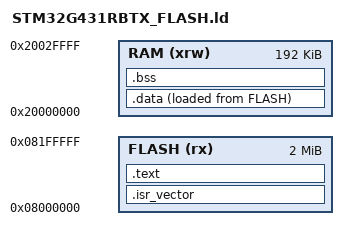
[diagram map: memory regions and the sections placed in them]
ENTRY(Reset_Handler)

_estack = 0x20030000;

MEMORY
{
    FLASH (rx) : ORIGIN = 0x08000000, LENGTH = 2048K
    RAM   (xrw): ORIGIN = 0x20000000, LENGTH = 192K
}

_sidata = LOADADDR(.data);

SECTIONS
{
    .isr_vector :
    {
        KEEP(*(.isr_vector))
    } > FLASH

    .text :
    {
        *(.text*)
        *(.rodata*)

        *(.init)
        *(.fini)

        . = ALIGN(4);
        _etext = .;
    } > FLASH

    .data :
    {
        . = ALIGN(4);
        _sdata = .;

        *(.data*)

        . = ALIGN(4);
        _edata = .;
    } > RAM AT > FLASH

    .bss :
    {
        . = ALIGN(4);
        _sbss = .;

        *(.bss*)
        *(COMMON)

        . = ALIGN(4);
        _ebss = .;
    } > RAM
}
